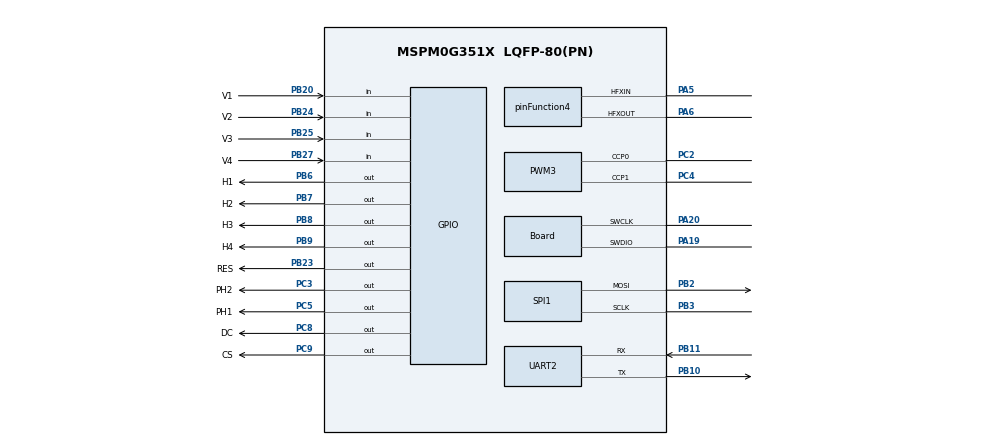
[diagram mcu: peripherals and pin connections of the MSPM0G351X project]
/**
 * @cliArgs --device "MSPM0G351X" --part "Default" --package "LQFP-80(PN)" --product "mspm0_sdk@2.08.00.03"
 * @versions {"tool":"1.25.0+4268"}
 */

/**
 * Import the modules used in this configuration.
 */
const GPIO   = scripting.addModule("/ti/driverlib/GPIO", {}, false);
const GPIO1  = GPIO.addInstance();
const GPIO2  = GPIO.addInstance();
const GPIO3  = GPIO.addInstance();
const PWM    = scripting.addModule("/ti/driverlib/PWM", {}, false);
const PWM3   = PWM.addInstance();
const SPI    = scripting.addModule("/ti/driverlib/SPI", {}, false);
const SPI1   = SPI.addInstance();
const SYSCTL = scripting.addModule("/ti/driverlib/SYSCTL");
const TRNG   = scripting.addModule("/ti/driverlib/TRNG");
const UART   = scripting.addModule("/ti/driverlib/UART", {}, false);
const UART2  = UART.addInstance();

/**
 * Write custom configuration values to the imported modules.
 */
const divider2       = system.clockTree["HFCLK4MFPCLKDIV"];
divider2.divideValue = 10;

const divider9       = system.clockTree["UDIV"];
divider9.divideValue = 2;

const gate7  = system.clockTree["MFCLKGATE"];
gate7.enable = true;

const gate8  = system.clockTree["MFPCLKGATE"];
gate8.enable = true;

const multiplier2         = system.clockTree["PLL_QDIV"];
multiplier2.multiplyValue = 4;

const mux4       = system.clockTree["EXHFMUX"];
mux4.inputSelect = "EXHFMUX_XTAL";

const mux8       = system.clockTree["HSCLKMUX"];
mux8.inputSelect = "HSCLKMUX_SYSPLL0";

const mux10       = system.clockTree["MFPCLKMUX"];
mux10.inputSelect = "MFPCLKMUX_HFCLK";

const mux12       = system.clockTree["SYSPLLMUX"];
mux12.inputSelect = "zSYSPLLMUX_HFCLK";

const pinFunction4                        = system.clockTree["HFXT"];
pinFunction4.inputFreq                    = 40;
pinFunction4.enable                       = true;
pinFunction4.HFXTStartup                  = 10;
pinFunction4.peripheral.$assign           = "SYSCTL";
pinFunction4.peripheral.hfxInPin.$assign  = "PA5";
pinFunction4.peripheral.hfxOutPin.$assign = "PA6";

const pinFunction6     = system.clockTree["LFXT"];
pinFunction6.inputFreq = 32.768;

GPIO1.$name                         = "OLED";
GPIO1.associatedPins.create(3);
GPIO1.associatedPins[0].$name       = "RES";
GPIO1.associatedPins[0].pin.$assign = "PB23";
GPIO1.associatedPins[1].$name       = "DC";
GPIO1.associatedPins[1].pin.$assign = "PC8";
GPIO1.associatedPins[2].$name       = "CS";
GPIO1.associatedPins[2].internalResistor = "PULL_UP";
GPIO1.associatedPins[2].pin.$assign = "PC9";

GPIO2.$name                              = "keyboard";
GPIO2.associatedPins.create(8);
GPIO2.associatedPins[0].$name            = "H1";
GPIO2.associatedPins[0].internalResistor = "PULL_UP";
GPIO2.associatedPins[0].pin.$assign      = "PB6";
GPIO2.associatedPins[1].$name            = "H2";
GPIO2.associatedPins[1].internalResistor = "PULL_UP";
GPIO2.associatedPins[1].pin.$assign      = "PB7";
GPIO2.associatedPins[2].$name            = "H3";
GPIO2.associatedPins[2].internalResistor = "PULL_UP";
GPIO2.associatedPins[2].pin.$assign      = "PB8";
GPIO2.associatedPins[3].$name            = "H4";
GPIO2.associatedPins[3].internalResistor = "PULL_UP";
GPIO2.associatedPins[3].pin.$assign      = "PB9";
GPIO2.associatedPins[4].$name            = "V1";
GPIO2.associatedPins[4].direction        = "INPUT";
GPIO2.associatedPins[4].internalResistor = "PULL_UP";
GPIO2.associatedPins[4].pin.$assign      = "PB20";
GPIO2.associatedPins[5].$name            = "V2";
GPIO2.associatedPins[5].direction        = "INPUT";
GPIO2.associatedPins[5].internalResistor = "PULL_UP";
GPIO2.associatedPins[5].pin.$assign      = "PB24";
GPIO2.associatedPins[6].$name            = "V3";
GPIO2.associatedPins[6].direction        = "INPUT";
GPIO2.associatedPins[6].internalResistor = "PULL_UP";
GPIO2.associatedPins[6].pin.$assign      = "PB25";
GPIO2.associatedPins[7].$name            = "V4";
GPIO2.associatedPins[7].direction        = "INPUT";
GPIO2.associatedPins[7].internalResistor = "PULL_UP";
GPIO2.associatedPins[7].pin.$assign      = "PB27";

GPIO3.$name                              = "MotorCtrl";
GPIO3.associatedPins.create(2);
GPIO3.associatedPins[0].$name            = "PH1";
GPIO3.associatedPins[0].direction        = "OUTPUT";
GPIO3.associatedPins[0].initialValue     = "SET";
GPIO3.associatedPins[0].internalResistor = "PULL_UP";
GPIO3.associatedPins[0].pin.$assign      = "PC5";
GPIO3.associatedPins[1].$name            = "PH2";
GPIO3.associatedPins[1].direction        = "OUTPUT";
GPIO3.associatedPins[1].initialValue     = "SET";
GPIO3.associatedPins[1].internalResistor = "PULL_UP";
GPIO3.associatedPins[1].pin.$assign      = "PC3";

PWM3.$name                              = "TimerA0_PWM";
PWM3.peripheral.$assign                 = "TIMA0";
PWM3.peripheral.ccp0Pin.$assign         = "PC2";
PWM3.peripheral.ccp1Pin.$assign         = "PC4";
PWM3.clockDivider                       = 8;
PWM3.clockPrescale                      = 10;
PWM3.timerStartTimer                    = true;
PWM3.PWM_CHANNEL_0.$name                = "ti_driverlib_pwm_PWMTimerCC4";
PWM3.PWM_CHANNEL_1.$name                = "ti_driverlib_pwm_PWMTimerCC5";
PWM3.ccp0PinConfig.direction            = scripting.forceWrite("OUTPUT");
PWM3.ccp0PinConfig.hideOutputInversion  = scripting.forceWrite(false);
PWM3.ccp0PinConfig.onlyInternalResistor = scripting.forceWrite(false);
PWM3.ccp0PinConfig.passedPeripheralType = scripting.forceWrite("Digital");
PWM3.ccp0PinConfig.$name                = "ti_driverlib_gpio_GPIOPinGeneric32";
PWM3.ccp1PinConfig.direction            = scripting.forceWrite("OUTPUT");
PWM3.ccp1PinConfig.hideOutputInversion  = scripting.forceWrite(false);
PWM3.ccp1PinConfig.onlyInternalResistor = scripting.forceWrite(false);
PWM3.ccp1PinConfig.passedPeripheralType = scripting.forceWrite("Digital");
PWM3.ccp1PinConfig.$name                = "ti_driverlib_gpio_GPIOPinGeneric33";

const Board                       = scripting.addModule("/ti/driverlib/Board", {}, false);
Board.peripheral.$assign          = "DEBUGSS";
Board.peripheral.swclkPin.$assign = "PA20";
Board.peripheral.swdioPin.$assign = "PA19";

SPI1.$name                      = "SPI_0";
SPI1.peripheral.$assign         = "SPI0";
SPI1.peripheral.sclkPin.$assign = "PB3";
SPI1.peripheral.mosiPin.$assign = "PB2";
SPI1.targetBitRate              = 20000000;
SPI1.frameFormat                = "MOTO3";
SPI1.polarity                   = "1";
SPI1.phase                      = "1";
SPI1.direction                  = "PICO";
SPI1.sclkPinConfig.$name        = "ti_driverlib_gpio_GPIOPinGeneric0";
SPI1.mosiPinConfig.$name        = "ti_driverlib_gpio_GPIOPinGeneric1";

SYSCTL.forceDefaultClkConfig = true;
SYSCTL.clockTreeEn           = true;

UART2.$name                    = "UART_4";
UART2.enableFIFO               = true;
UART2.enableDMARX              = false;
UART2.enableDMATX              = false;
UART2.peripheral.$assign       = "UART4";
UART2.peripheral.rxPin.$assign = "PB11";
UART2.peripheral.txPin.$assign = "PB10";

TRNG.clockDivider = "DL_TRNG_CLOCK_DIVIDE_8";

const ProjectConfig              = scripting.addModule("/ti/project_config/ProjectConfig", {}, false);
ProjectConfig.migrationCondition = true;
